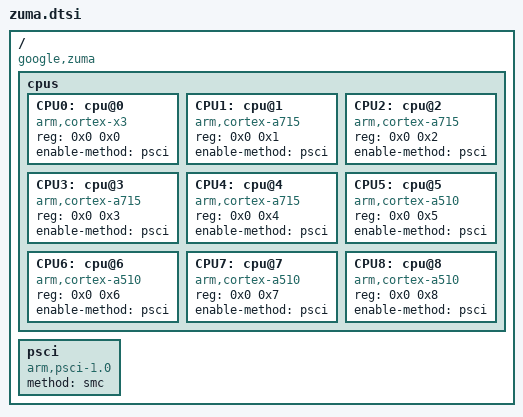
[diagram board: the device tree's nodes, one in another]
// SPDX-License-Identifier: GPL-2.0-only
/* Google Tensor G3 ("Zuma") SoC - minimal skeleton (standalone) */
#include <dt-bindings/interrupt-controller/arm-gic.h>

/ {
	compatible = "google,zuma";
	#address-cells = <2>;
	#size-cells = <2>;

	cpus {
		#address-cells = <2>;
		#size-cells = <0>;
		CPU0: cpu@0 { device_type = "cpu"; compatible = "arm,cortex-x3";   reg = <0x0 0x0>; enable-method = "psci"; };
		CPU1: cpu@1 { device_type = "cpu"; compatible = "arm,cortex-a715"; reg = <0x0 0x1>; enable-method = "psci"; };
		CPU2: cpu@2 { device_type = "cpu"; compatible = "arm,cortex-a715"; reg = <0x0 0x2>; enable-method = "psci"; };
		CPU3: cpu@3 { device_type = "cpu"; compatible = "arm,cortex-a715"; reg = <0x0 0x3>; enable-method = "psci"; };
		CPU4: cpu@4 { device_type = "cpu"; compatible = "arm,cortex-a715"; reg = <0x0 0x4>; enable-method = "psci"; };
		CPU5: cpu@5 { device_type = "cpu"; compatible = "arm,cortex-a510"; reg = <0x0 0x5>; enable-method = "psci"; };
		CPU6: cpu@6 { device_type = "cpu"; compatible = "arm,cortex-a510"; reg = <0x0 0x6>; enable-method = "psci"; };
		CPU7: cpu@7 { device_type = "cpu"; compatible = "arm,cortex-a510"; reg = <0x0 0x7>; enable-method = "psci"; };
		CPU8: cpu@8 { device_type = "cpu"; compatible = "arm,cortex-a510"; reg = <0x0 0x8>; enable-method = "psci"; };
	};

	psci { compatible = "arm,psci-1.0"; method = "smc"; };
};
